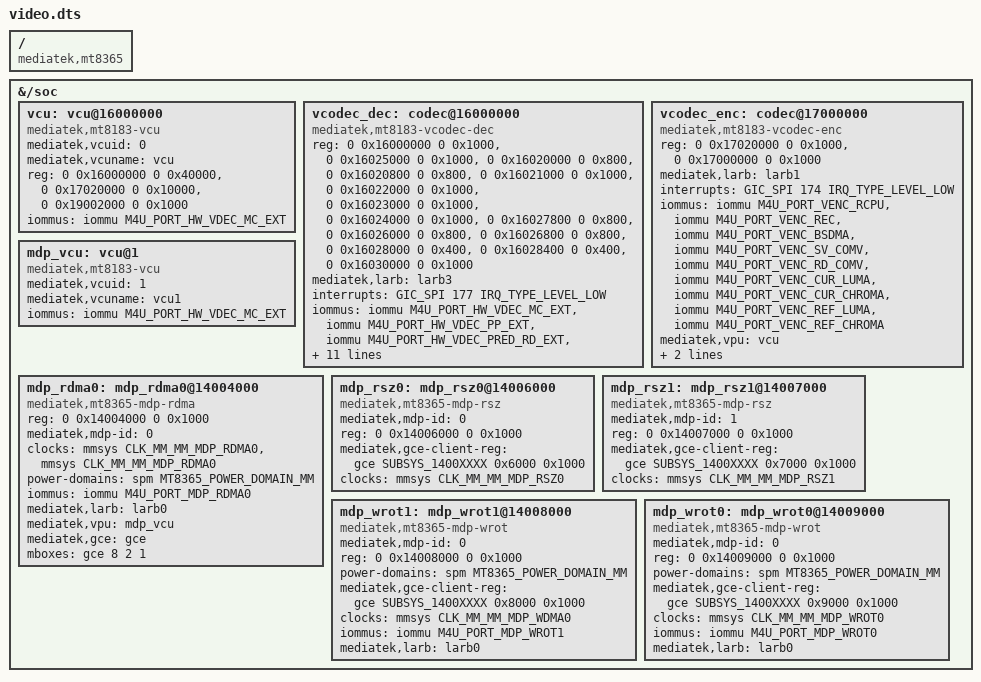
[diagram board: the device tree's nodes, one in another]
// SPDX-License-Identifier: (GPL-2.0 OR MIT)
/*
 * Copyright (c) 2021 MediaTek Inc.
 * Author: Macross Chen <macross.chen@mediatek.com>
 */

/dts-v1/;
/plugin/;

#include <dt-bindings/clock/mt8365-clk.h>
#include <dt-bindings/gce/mt8365-gce.h>
#include <dt-bindings/interrupt-controller/arm-gic.h>
#include <dt-bindings/interrupt-controller/irq.h>
#include <dt-bindings/memory/mt8365-larb-port.h>
#include <dt-bindings/power/mt8365-power.h>

/ {
	compatible = "mediatek,mt8365";

	fragment@0 {
		target-path = "/soc";
		__overlay__ {
			vcu: vcu@16000000 {
				compatible = "mediatek,mt8183-vcu";
				mediatek,vcuid = <0>;
				mediatek,vcuname = "vcu";
				reg = <0 0x16000000 0 0x40000>,	    /* VDEC_BASE */
					 <0 0x17020000 0 0x10000>,  /* VENC_BASE */
					 <0 0x19002000 0 0x1000>;   /* VENC_LT */
				iommus = <&iommu M4U_PORT_HW_VDEC_MC_EXT>;
			};

			vcodec_dec: codec@16000000 {
				compatible = "mediatek,mt8183-vcodec-dec",
							"syscon";
				reg = <0 0x16000000 0 0x1000>,		/* VDEC_SYS */
					  <0 0x16025000 0 0x1000>,		/* VDEC_MISC */
					  <0 0x16020000 0 0x800>,		/* VDEC_VLD */
					  <0 0x16020800 0 0x800>,		/* VDEC_TOP */
					  <0 0x16021000 0 0x1000>,		/* VDEC_MC */
					  <0 0x16022000 0 0x1000>,		/* VDEC_AVC_VLD */
					  <0 0x16023000 0 0x1000>,		/* VDEC_AVC_MV */
					  <0 0x16024000 0 0x1000>,		/* VDEC_PP */
					  <0 0x16027800 0 0x800>,		/* VP8_VLD */
					  <0 0x16026000 0 0x800>,		/* VP6_VD */
					  <0 0x16026800 0 0x800>,		/* VP8_VLD2 */
					  <0 0x16028000 0 0x400>,		/* HEVC_VLD */
					  <0 0x16028400 0 0x400>,		/* VP9_VLD */
					  <0 0x16030000 0 0x1000>;		/* IMAGE_RESZ */
				mediatek,larb = <&larb3>;
				interrupts = <GIC_SPI 177 IRQ_TYPE_LEVEL_LOW>;
				iommus =
					<&iommu M4U_PORT_HW_VDEC_MC_EXT>,
					<&iommu M4U_PORT_HW_VDEC_PP_EXT>,
					<&iommu M4U_PORT_HW_VDEC_PRED_RD_EXT>,
					<&iommu M4U_PORT_HW_VDEC_PRED_WR_EXT>,
					<&iommu M4U_PORT_HW_VDEC_PPWRAP_EXT>,
					<&iommu M4U_PORT_HW_VDEC_TILE_EXT>,
					<&iommu M4U_PORT_HW_VDEC_VLD_EXT>,
					<&iommu M4U_PORT_HW_VDEC_VLD2_EXT>,
					<&iommu M4U_PORT_HW_VDEC_AVC_MV_EXT>,
					<&iommu M4U_PORT_HW_VDEC_RG_CTRL_DMA_EXT>;
				mediatek,vpu = <&vcu>;
				power-domains = <&spm MT8365_POWER_DOMAIN_VDEC>;
				clocks =
					<&vdecsys CLK_VDEC_VDEC>,
					<&vdecsys CLK_VDEC_LARB1>;
				clock-names =
					"vdec_sel",
					"normal";
				#clock-cells = <1>;
			};

			vcodec_enc: codec@17000000 {
				compatible = "mediatek,mt8183-vcodec-enc";
				reg = <0 0x17020000 0 0x1000>,
					<0 0x17000000 0 0x1000>;
				mediatek,larb = <&larb1>;
				interrupts = <GIC_SPI 174 IRQ_TYPE_LEVEL_LOW>;
				iommus =
					<&iommu M4U_PORT_VENC_RCPU>,
					<&iommu M4U_PORT_VENC_REC>,
					<&iommu M4U_PORT_VENC_BSDMA>,
					<&iommu M4U_PORT_VENC_SV_COMV>,
					<&iommu M4U_PORT_VENC_RD_COMV>,
					<&iommu M4U_PORT_VENC_CUR_LUMA>,
					<&iommu M4U_PORT_VENC_CUR_CHROMA>,
					<&iommu M4U_PORT_VENC_REF_LUMA>,
					<&iommu M4U_PORT_VENC_REF_CHROMA>;
				mediatek,vpu = <&vcu>;
				power-domains = <&spm MT8365_POWER_DOMAIN_VENC>;
				clocks = <&vencsys CLK_VENC>;
				clock-names = "img_venc";
				#clock-cells = <1>;
			};

			mdp_vcu: vcu@1 {
				compatible = "mediatek,mt8183-vcu";
				mediatek,vcuid = <1>;
				mediatek,vcuname = "vcu1";
				iommus = <&iommu M4U_PORT_HW_VDEC_MC_EXT>;
			};

			mdp_rdma0: mdp_rdma0@14004000 {
				compatible = "mediatek,mt8365-mdp-rdma",
							"mediatek,mt8167-mdp-rdma",
							"mediatek,mt8167-mdp";
				reg = <0 0x14004000 0 0x1000>;
				mediatek,mdp-id = <0>;
				clocks = <&mmsys CLK_MM_MM_MDP_RDMA0>,
					 <&mmsys CLK_MM_MM_MDP_RDMA0>;
				power-domains = <&spm MT8365_POWER_DOMAIN_MM>;
				iommus = <&iommu M4U_PORT_MDP_RDMA0>;
				mediatek,larb = <&larb0>;
				mediatek,vpu = <&mdp_vcu>;
				mediatek,gce = <&gce>;
				mboxes = <&gce 8 2 1>;
			};

			mdp_rsz0: mdp_rsz0@14006000 {
				compatible = "mediatek,mt8365-mdp-rsz",
							"mediatek,mt8167-mdp-rsz";
				mediatek,mdp-id = <0>;
				reg = <0 0x14006000 0 0x1000>;
				mediatek,gce-client-reg = <&gce SUBSYS_1400XXXX 0x6000 0x1000>;
				clocks = <&mmsys CLK_MM_MM_MDP_RSZ0>;
			};

			mdp_rsz1: mdp_rsz1@14007000 {
				compatible = "mediatek,mt8365-mdp-rsz",
							"mediatek,mt8167-mdp-rsz";
				mediatek,mdp-id = <1>;
				reg = <0 0x14007000 0 0x1000>;
				mediatek,gce-client-reg = <&gce SUBSYS_1400XXXX 0x7000 0x1000>;
				clocks = <&mmsys CLK_MM_MM_MDP_RSZ1>;
			};

			mdp_wrot1: mdp_wrot1@14008000 {
				compatible = "mediatek,mt8365-mdp-wrot",
							"mediatek,mt8167-mdp-wrot";
				mediatek,mdp-id = <0>;
				reg = <0 0x14008000 0 0x1000>;
				power-domains = <&spm MT8365_POWER_DOMAIN_MM>;
				mediatek,gce-client-reg = <&gce SUBSYS_1400XXXX 0x8000 0x1000>;
				clocks = <&mmsys CLK_MM_MM_MDP_WDMA0>;
				iommus = <&iommu M4U_PORT_MDP_WROT1>;
				mediatek,larb = <&larb0>;
			};

			mdp_wrot0: mdp_wrot0@14009000 {
				compatible = "mediatek,mt8365-mdp-wrot",
							"mediatek,mt8167-mdp-wrot";
				mediatek,mdp-id = <0>;
				reg = <0 0x14009000 0 0x1000>;
				power-domains = <&spm MT8365_POWER_DOMAIN_MM>;
				mediatek,gce-client-reg = <&gce SUBSYS_1400XXXX 0x9000 0x1000>;
				clocks = <&mmsys CLK_MM_MM_MDP_WROT0>;
				iommus = <&iommu M4U_PORT_MDP_WROT0>;
				mediatek,larb = <&larb0>;
			};
		};
	};
};
